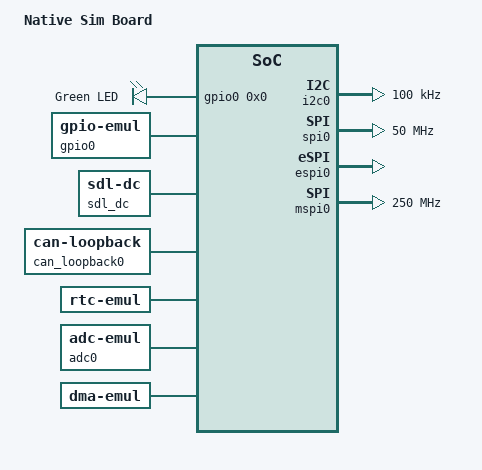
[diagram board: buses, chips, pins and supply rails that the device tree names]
/dts-v1/;

/* node '/' defined in zephyr/dts/common/skeleton.dtsi:9 */
/ {
	#address-cells = < 0x1 >;    /* in zephyr/dts/common/skeleton.dtsi:10 */
	#size-cells = < 0x1 >;       /* in zephyr/dts/common/skeleton.dtsi:11 */
	model = "Native Sim Board";  /* in zephyr/boards/native/native_sim/native_sim.dts:14 */
	compatible = "zephyr,posix"; /* in zephyr/boards/native/native_sim/native_sim.dts:15 */

	/* node '/chosen' defined in zephyr/dts/common/skeleton.dtsi:12 */
	chosen {
		zephyr,console = &uart0;                     /* in zephyr/boards/native/native_sim/native_sim.dts:18 */
		zephyr,shell-uart = &uart0;                  /* in zephyr/boards/native/native_sim/native_sim.dts:19 */
		zephyr,uart-mcumgr = &uart0;                 /* in zephyr/boards/native/native_sim/native_sim.dts:20 */
		zephyr,flash = &flash0;                      /* in zephyr/boards/native/native_sim/native_sim.dts:21 */
		zephyr,entropy = &rng;                       /* in zephyr/boards/native/native_sim/native_sim.dts:22 */
		zephyr,flash-controller = &flashcontroller0; /* in zephyr/boards/native/native_sim/native_sim.dts:23 */
		zephyr,display = &sdl_dc;                    /* in zephyr/boards/native/native_sim/native_sim.dts:24 */
		zephyr,canbus = &can_loopback0;              /* in zephyr/boards/native/native_sim/native_sim.dts:25 */
		zephyr,code-partition = &slot0_partition;    /* in zephyr/boards/native/native_sim/native_sim.dts:26 */
		zephyr,bt-hci = &bt_hci_userchan;            /* in zephyr/boards/native/native_sim/native_sim.dts:27 */
		zephyr,touch = &input_sdl_touch;             /* in zephyr/boards/native/native_sim/native_sim.dts:28 */
	};

	/* node '/aliases' defined in zephyr/dts/common/skeleton.dtsi:13 */
	aliases {
		eeprom-0 = &eeprom0; /* in zephyr/boards/native/native_sim/native_sim.dts:32 */
		i2c-0 = &i2c0;       /* in zephyr/boards/native/native_sim/native_sim.dts:33 */
		spi-0 = &spi0;       /* in zephyr/boards/native/native_sim/native_sim.dts:34 */
		led0 = &led0;        /* in zephyr/boards/native/native_sim/native_sim.dts:35 */
		rtc = &rtc;          /* in zephyr/boards/native/native_sim/native_sim.dts:36 */
	};

	/* node '/leds' defined in zephyr/boards/native/native_sim/native_sim.dts:39 */
	leds {
		compatible = "gpio-leds"; /* in zephyr/boards/native/native_sim/native_sim.dts:40 */

		/* node '/leds/led_0' defined in zephyr/boards/native/native_sim/native_sim.dts:41 */
		led0: led_0 {
			gpios = < &gpio0 0x0 0x0 >; /* in zephyr/boards/native/native_sim/native_sim.dts:42 */
			label = "Green LED";        /* in zephyr/boards/native/native_sim/native_sim.dts:43 */
		};
	};

	/* node '/lvgl_pointer' defined in zephyr/boards/native/native_sim/native_sim.dts:47 */
	lvgl_pointer {
		compatible = "zephyr,lvgl-pointer-input"; /* in zephyr/boards/native/native_sim/native_sim.dts:48 */
		input = < &input_sdl_touch >;             /* in zephyr/boards/native/native_sim/native_sim.dts:49 */
	};

	/* node '/cpus' defined in zephyr/boards/native/native_sim/native_sim.dts:52 */
	cpus {
		#address-cells = < 0x1 >; /* in zephyr/boards/native/native_sim/native_sim.dts:53 */
		#size-cells = < 0x0 >;    /* in zephyr/boards/native/native_sim/native_sim.dts:54 */

		/* node '/cpus/cpu@0' defined in zephyr/boards/native/native_sim/native_sim.dts:56 */
		cpu0: cpu@0 {
			compatible = "zephyr,native-sim-cpu"; /* in zephyr/boards/native/native_sim/native_sim.dts:57 */
			reg = < 0x0 >;                        /* in zephyr/boards/native/native_sim/native_sim.dts:58 */
		};
	};

	/* node '/flash-controller@0' defined in zephyr/boards/native/native_sim/native_sim.dts:62 */
	flashcontroller0: flash-controller@0 {
		compatible = "zephyr,sim-flash"; /* in zephyr/boards/native/native_sim/native_sim.dts:63 */
		reg = < 0x0 0x200000 >;          /* in zephyr/boards/native/native_sim/native_sim.dts:64 */
		#address-cells = < 0x1 >;        /* in zephyr/boards/native/native_sim/native_sim.dts:66 */
		#size-cells = < 0x1 >;           /* in zephyr/boards/native/native_sim/native_sim.dts:67 */
		erase-value = < 0xff >;          /* in zephyr/boards/native/native_sim/native_sim.dts:68 */

		/* node '/flash-controller@0/flash@0' defined in zephyr/boards/native/native_sim/native_sim.dts:70 */
		flash0: flash@0 {
			status = "okay";               /* in zephyr/boards/native/native_sim/native_sim.dts:71 */
			compatible = "soc-nv-flash";   /* in zephyr/boards/native/native_sim/native_sim.dts:72 */
			erase-block-size = < 0x1000 >; /* in zephyr/boards/native/native_sim/native_sim.dts:73 */
			write-block-size = < 0x1 >;    /* in zephyr/boards/native/native_sim/native_sim.dts:74 */
			reg = < 0x0 0x200000 >;        /* in zephyr/boards/native/native_sim/native_sim.dts:75 */

			/* node '/flash-controller@0/flash@0/partitions' defined in zephyr/boards/native/native_sim/native_sim.dts:77 */
			partitions {
				compatible = "fixed-partitions"; /* in zephyr/boards/native/native_sim/native_sim.dts:78 */
				#address-cells = < 0x1 >;        /* in zephyr/boards/native/native_sim/native_sim.dts:79 */
				#size-cells = < 0x1 >;           /* in zephyr/boards/native/native_sim/native_sim.dts:80 */

				/* node '/flash-controller@0/flash@0/partitions/partition@0' defined in zephyr/boards/native/native_sim/native_sim.dts:82 */
				boot_partition: partition@0 {
					label = "mcuboot";    /* in zephyr/boards/native/native_sim/native_sim.dts:83 */
					reg = < 0x0 0xc000 >; /* in zephyr/boards/native/native_sim/native_sim.dts:84 */
				};

				/* node '/flash-controller@0/flash@0/partitions/partition@c000' defined in zephyr/boards/native/native_sim/native_sim.dts:86 */
				slot0_partition: partition@c000 {
					label = "image-0";        /* in zephyr/boards/native/native_sim/native_sim.dts:87 */
					reg = < 0xc000 0x69000 >; /* in zephyr/boards/native/native_sim/native_sim.dts:88 */
				};

				/* node '/flash-controller@0/flash@0/partitions/partition@75000' defined in zephyr/boards/native/native_sim/native_sim.dts:90 */
				slot1_partition: partition@75000 {
					label = "image-1";         /* in zephyr/boards/native/native_sim/native_sim.dts:91 */
					reg = < 0x75000 0x69000 >; /* in zephyr/boards/native/native_sim/native_sim.dts:92 */
				};

				/* node '/flash-controller@0/flash@0/partitions/partition@de000' defined in zephyr/boards/native/native_sim/native_sim.dts:94 */
				scratch_partition: partition@de000 {
					label = "image-scratch";   /* in zephyr/boards/native/native_sim/native_sim.dts:95 */
					reg = < 0xde000 0x1e000 >; /* in zephyr/boards/native/native_sim/native_sim.dts:96 */
				};

				/* node '/flash-controller@0/flash@0/partitions/partition@fc000' defined in zephyr/boards/native/native_sim/native_sim.dts:98 */
				storage_partition: partition@fc000 {
					label = "storage";        /* in zephyr/boards/native/native_sim/native_sim.dts:99 */
					reg = < 0xfc000 0x4000 >; /* in zephyr/boards/native/native_sim/native_sim.dts:100 */
				};
			};
		};
	};

	/* node '/eeprom' defined in zephyr/boards/native/native_sim/native_sim.dts:106 */
	eeprom0: eeprom {
		status = "okay";                  /* in zephyr/boards/native/native_sim/native_sim.dts:107 */
		compatible = "zephyr,sim-eeprom"; /* in zephyr/boards/native/native_sim/native_sim.dts:108 */
		size = < 0x8000 >;                /* in zephyr/boards/native/native_sim/native_sim.dts:109 */
	};

	/* node '/i2c@100' defined in zephyr/boards/native/native_sim/native_sim.dts:112 */
	i2c0: i2c@100 {
		status = "okay";                           /* in zephyr/boards/native/native_sim/native_sim.dts:113 */
		compatible = "zephyr,i2c-emul-controller"; /* in zephyr/boards/native/native_sim/native_sim.dts:114 */
		clock-frequency = < 0x186a0 >;             /* in zephyr/boards/native/native_sim/native_sim.dts:115 */
		#address-cells = < 0x1 >;                  /* in zephyr/boards/native/native_sim/native_sim.dts:116 */
		#size-cells = < 0x0 >;                     /* in zephyr/boards/native/native_sim/native_sim.dts:117 */
		#forward-cells = < 0x1 >;                  /* in zephyr/boards/native/native_sim/native_sim.dts:118 */
		reg = < 0x100 0x4 >;                       /* in zephyr/boards/native/native_sim/native_sim.dts:119 */
	};

	/* node '/spi@200' defined in zephyr/boards/native/native_sim/native_sim.dts:122 */
	spi0: spi@200 {
		status = "okay";                           /* in zephyr/boards/native/native_sim/native_sim.dts:123 */
		compatible = "zephyr,spi-emul-controller"; /* in zephyr/boards/native/native_sim/native_sim.dts:124 */
		clock-frequency = < 0x2faf080 >;           /* in zephyr/boards/native/native_sim/native_sim.dts:125 */
		#address-cells = < 0x1 >;                  /* in zephyr/boards/native/native_sim/native_sim.dts:126 */
		#size-cells = < 0x0 >;                     /* in zephyr/boards/native/native_sim/native_sim.dts:127 */
		reg = < 0x200 0x4 >;                       /* in zephyr/boards/native/native_sim/native_sim.dts:128 */
	};

	/* node '/espi@300' defined in zephyr/boards/native/native_sim/native_sim.dts:131 */
	espi0: espi@300 {
		status = "okay";                            /* in zephyr/boards/native/native_sim/native_sim.dts:132 */
		compatible = "zephyr,espi-emul-controller"; /* in zephyr/boards/native/native_sim/native_sim.dts:133 */
		reg = < 0x300 0x4 >;                        /* in zephyr/boards/native/native_sim/native_sim.dts:134 */
		#address-cells = < 0x1 >;                   /* in zephyr/boards/native/native_sim/native_sim.dts:135 */
		#size-cells = < 0x0 >;                      /* in zephyr/boards/native/native_sim/native_sim.dts:136 */
	};

	/* node '/mspi@400' defined in zephyr/boards/native/native_sim/native_sim.dts:139 */
	mspi0: mspi@400 {
		status = "okay";                            /* in zephyr/boards/native/native_sim/native_sim.dts:140 */
		compatible = "zephyr,mspi-emul-controller"; /* in zephyr/boards/native/native_sim/native_sim.dts:141 */
		clock-frequency = < 0xee6b280 >;            /* in zephyr/boards/native/native_sim/native_sim.dts:142 */
		reg = < 0x400 0x4 >;                        /* in zephyr/boards/native/native_sim/native_sim.dts:143 */
		#address-cells = < 0x1 >;                   /* in zephyr/boards/native/native_sim/native_sim.dts:144 */
		#size-cells = < 0x0 >;                      /* in zephyr/boards/native/native_sim/native_sim.dts:145 */
	};

	/* node '/uart' defined in zephyr/boards/native/native_sim/native_sim.dts:148 */
	uart0: uart {
		status = "okay";                       /* in zephyr/boards/native/native_sim/native_sim.dts:149 */
		compatible = "zephyr,native-pty-uart"; /* in zephyr/boards/native/native_sim/native_sim.dts:150 */
		current-speed = < 0x0 >;               /* in zephyr/boards/native/native_sim/native_sim.dts:154 */
	};

	/* node '/uart_1' defined in zephyr/boards/native/native_sim/native_sim.dts:157 */
	uart1: uart_1 {
		status = "disabled";                   /* in zephyr/boards/native/native_sim/native_sim.dts:158 */
		compatible = "zephyr,native-pty-uart"; /* in zephyr/boards/native/native_sim/native_sim.dts:159 */
		current-speed = < 0x0 >;               /* in zephyr/boards/native/native_sim/native_sim.dts:163 */
	};

	/* node '/rng' defined in zephyr/boards/native/native_sim/native_sim.dts:166 */
	rng: rng {
		status = "okay";                      /* in zephyr/boards/native/native_sim/native_sim.dts:167 */
		compatible = "zephyr,native-sim-rng"; /* in zephyr/boards/native/native_sim/native_sim.dts:168 */
	};

	/* node '/counter' defined in zephyr/boards/native/native_sim/native_sim.dts:171 */
	counter0: counter {
		status = "okay";                          /* in zephyr/boards/native/native_sim/native_sim.dts:172 */
		compatible = "zephyr,native-sim-counter"; /* in zephyr/boards/native/native_sim/native_sim.dts:173 */
	};

	/* node '/gpio_emul' defined in zephyr/boards/native/native_sim/native_sim.dts:176 */
	gpio0: gpio_emul {
		status = "okay";                 /* in zephyr/boards/native/native_sim/native_sim.dts:177 */
		compatible = "zephyr,gpio-emul"; /* in zephyr/boards/native/native_sim/native_sim.dts:178 */
		rising-edge;                     /* in zephyr/boards/native/native_sim/native_sim.dts:179 */
		falling-edge;                    /* in zephyr/boards/native/native_sim/native_sim.dts:180 */
		high-level;                      /* in zephyr/boards/native/native_sim/native_sim.dts:181 */
		low-level;                       /* in zephyr/boards/native/native_sim/native_sim.dts:182 */
		gpio-controller;                 /* in zephyr/boards/native/native_sim/native_sim.dts:183 */
		#gpio-cells = < 0x2 >;           /* in zephyr/boards/native/native_sim/native_sim.dts:184 */
		phandle = < 0x1 >;               /* in zephyr/boards/native/native_sim/native_sim.dts:42 */
	};

	/* node '/udc0' defined in zephyr/boards/native/native_sim/native_sim.dts:187 */
	zephyr_udc0: udc0 {
		compatible = "zephyr,native-posix-udc"; /* in zephyr/boards/native/native_sim/native_sim.dts:188 */
	};

	/* node '/sdl_dc' defined in zephyr/boards/native/native_sim/native_sim.dts:191 */
	sdl_dc: sdl_dc {
		compatible = "zephyr,sdl-dc"; /* in zephyr/boards/native/native_sim/native_sim.dts:192 */
		height = < 0xf0 >;            /* in zephyr/boards/native/native_sim/native_sim.dts:193 */
		width = < 0x140 >;            /* in zephyr/boards/native/native_sim/native_sim.dts:194 */
		phandle = < 0x3 >;            /* in zephyr/boards/native/native_sim/native_sim.dts:199 */
	};

	/* node '/input-sdl-touch' defined in zephyr/boards/native/native_sim/native_sim.dts:197 */
	input_sdl_touch: input-sdl-touch {
		compatible = "zephyr,input-sdl-touch"; /* in zephyr/boards/native/native_sim/native_sim.dts:198 */
		display = < &sdl_dc >;                 /* in zephyr/boards/native/native_sim/native_sim.dts:199 */
		phandle = < 0x2 >;                     /* in zephyr/boards/native/native_sim/native_sim.dts:49 */
	};

	/* node '/can_loopback0' defined in zephyr/boards/native/native_sim/native_sim.dts:202 */
	can_loopback0: can_loopback0 {
		status = "okay";                    /* in zephyr/boards/native/native_sim/native_sim.dts:203 */
		compatible = "zephyr,can-loopback"; /* in zephyr/boards/native/native_sim/native_sim.dts:204 */
	};

	/* node '/can' defined in zephyr/boards/native/native_sim/native_sim.dts:207 */
	can0: can {
		status = "disabled";                    /* in zephyr/boards/native/native_sim/native_sim.dts:208 */
		compatible = "zephyr,native-linux-can"; /* in zephyr/boards/native/native_sim/native_sim.dts:209 */
		host-interface = "zcan0";               /* in zephyr/boards/native/native_sim/native_sim.dts:213 */
	};

	/* node '/rtc' defined in zephyr/boards/native/native_sim/native_sim.dts:216 */
	rtc: rtc {
		status = "okay";                /* in zephyr/boards/native/native_sim/native_sim.dts:217 */
		compatible = "zephyr,rtc-emul"; /* in zephyr/boards/native/native_sim/native_sim.dts:218 */
		alarms-count = < 0x2 >;         /* in zephyr/boards/native/native_sim/native_sim.dts:219 */
	};

	/* node '/adc' defined in zephyr/boards/native/native_sim/native_sim.dts:222 */
	adc0: adc {
		compatible = "zephyr,adc-emul"; /* in zephyr/boards/native/native_sim/native_sim.dts:223 */
		nchannels = < 0x2 >;            /* in zephyr/boards/native/native_sim/native_sim.dts:224 */
		#io-channel-cells = < 0x1 >;    /* in zephyr/boards/native/native_sim/native_sim.dts:225 */
		status = "okay";                /* in zephyr/boards/native/native_sim/native_sim.dts:226 */
	};

	/* node '/dma' defined in zephyr/boards/native/native_sim/native_sim.dts:229 */
	dma: dma {
		compatible = "zephyr,dma-emul"; /* in zephyr/boards/native/native_sim/native_sim.dts:230 */
		#dma-cells = < 0x1 >;           /* in zephyr/boards/native/native_sim/native_sim.dts:231 */
		stack-size = < 0x1000 >;        /* in zephyr/boards/native/native_sim/native_sim.dts:232 */
	};

	/* node '/bt_hci_userchan' defined in zephyr/boards/native/native_sim/native_sim.dts:235 */
	bt_hci_userchan: bt_hci_userchan {
		compatible = "zephyr,bt-hci-userchan"; /* in zephyr/boards/native/native_sim/native_sim.dts:236 */
		status = "okay";                       /* in zephyr/boards/native/native_sim/native_sim.dts:237 */
	};
};
